# R7FA8D1BH register map
Vendor: Renesas; Series: RA8; File version: 1.2
CPU: CM85 r0p0, little endian, MPU, FPU, VTOR, 4 interrupt priority bits
Registers are 32-bit, read-write, reset 0x0 unless marked. A register's access mark holds for its fields unless they carry their own. Offsets are from the block's base; [hi:lo] are bit positions; lines under a group give offsets from that group; {n}, {i} and the like mark numbered series.

## WDT — Watchdog Timer
Base 0x40202600
Same registers: WDT_NS 0x50202600
0x00 WDTRR 8-bit reset 0xFF — WDT Refresh Register
  [7:0] WDTRR — WDTRR is an 8-bit register that refreshes the down-counter of the WDT.
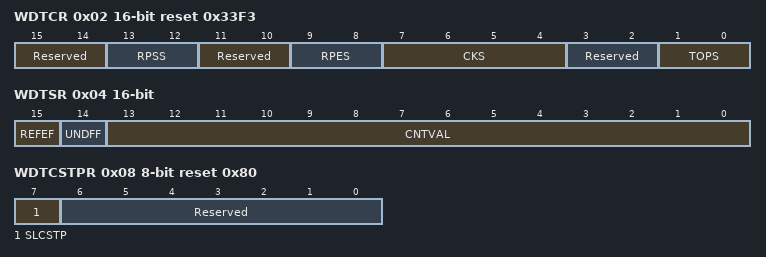
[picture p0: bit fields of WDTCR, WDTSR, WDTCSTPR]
0x02 WDTCR 16-bit reset 0x33F3 — WDT Control Register
  [15:14] Reserved — These bits are read as 00. The write value should be 00.
  [13:12] RPSS — Window Start Position Selection
    0=25 percent; 1=50 percent; 2=75 percent; 3=100 percent (window start position is not specified)
  [11:10] Reserved — These bits are read as 00. The write value should be 00.
  [9:8] RPES — Window End Position Selection
    0=75 percent; 1=50 percent; 2=25 percent; 3=0 percent (window end position is not specified)
  [7:4] CKS — Clock Division Ratio Selection
    1=PCLK/4; 4=PCLK/64; 15=PCLK/128; 6=PCLK/512; 7=PCLK/2048; 8=PCLK/8192; other=others (setting prohibited)
  [3:2] Reserved — These bits are read as 00. The write value should be 00.
  [1:0] TOPS — Timeout Period Selection
    0=1,024 cycles (03FFh); 1=4,096 cycles (0FFFh); 2=8,192 cycles (1FFFh); 3=16,384 cycles (3FFFh)
0x04 WDTSR 16-bit — WDT Status Register
  [15] REFEF write-0-clears read-modifies — Refresh Error Flag
    0=No refresh error occurred; 1=Refresh error occurred
  [14] UNDFF write-0-clears read-modifies — Underflow Flag
    0=No underflow occurred; 1=Underflow occurred
  [13:0] CNTVAL ro — Down-Counter ValueValue counted by the down-counter
0x06 WDTRCR 8-bit reset 0x80 — WDT Reset Control Register
  [7] RSTIRQS — Reset Interrupt Request Selection
    0=Non-maskable interrupt request or interrupt request output is enabled; 1=Reset output is enabled
0x08 WDTCSTPR 8-bit reset 0x80 — WDT Count Stop Control Register
  [7] SLCSTP — Sleep-Mode Count Stop Control
    0=Count stop is disabled; 1=Count is stopped at a transition to sleep mode
  [6:0] Reserved — These bits are read as 0000000. The write value should be 0000000.

## POEG — Port Output Enable Module for GPT
Base 0x40212000
Same registers: POEG_NS 0x50212000
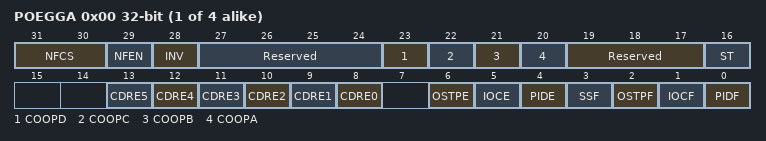
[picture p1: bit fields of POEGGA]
0x00 POEGG{x} (x=A,B,C,D; step 0x100) — POEG Group {x} Setting Register
  [31:30] NFCS — Noise Filter Clock Select
    0=Sampling GTETRG pin input level for three times in every PCLKB; 1=Sampling GTETRG pin input level for three times in every PCLKB /8; 2=Sampling GTETRG pin input level for three times in every PCLKB /32; 3=Sampling GTETRG pin input level for three times in every PCLKB /128
  [29] NFEN — Noise Filter Enable
    0=Filtering noise disabled; 1=Filtering noise enabled
  [28] INV — GTETRG Input Reverse
    0=GTETRG Input; 1=GTETRG Input Reversed
  [27:24] Reserved — These bits are read as 0000. The write value should be 0000.
  [23] COOPD — POEG group D Cooperation Enable
    0=Disable cooperation with POEG group D; 1=Enable cooperation with POEG group D
  [22] COOPC — POEG group C Cooperation Enable
    0=Disable cooperation with POEG group C; 1=Enable cooperation with POEG group C
  [21] COOPB — POEG group B Cooperation Enable
    0=Disable cooperation with POEG group B; 1=Enable cooperation with POEG group B
  [20] COOPA — POEG group A Cooperation Enable
    0=Disable cooperation with POEG group A; 1=Enable cooperation with POEG group A
  [19:17] Reserved — These bits are read as 000. The write value should be 000.
  [16] ST ro — GTETRG Input Status Flag
    0=GTETRG input after filtering is 0; 1=GTETRG input after filtering is 1
  [n+8] CDRE{n} (n=0..5) — Comparator Disable Request Enable {n}Note: Can be modified only once after a reset.
    0=A disable request of comparator {n} disabled; 1=A disable request of comparator {n} enabled
  [6] OSTPE — Oscillation Stop Detection EnableNote: Can be modified only once after a reset.
    0=A output-disable request from the oscillation stop detection disabled; 1=A output-disable request from the oscillation stop detection enabled
  [5] IOCE — Enable for GPT Output-Disable RequestNote: Can be modified only once after a reset.
    0=Disable output-disable requests from GPT disable request; 1=Enable output-disable requests from GPT disable request
  [4] PIDE — Port Input Detection EnableNote: Can be modified only once after a reset.
    0=A output-disable request from the GTETRG pins disabled; 1=A output-disable request from the GTETRG pins enabled
  [3] SSF — Software Stop Flag
    0=A output-disable request from software has not been generated; 1=A output-disable request from software has been generated
  [2] OSTPF write-0-clears read-modifies — Oscillation Stop Detection Flag
    0=A output-disable request from the oscillation stop detection has not been generated; 1=A output-disable request from the oscillation stop detection has been generated
  [1] IOCF write-0-clears read-modifies — Real Time Overcurrent Detection Flag
    0=A output-disable request from GPT disable request or comparator interrupt has not been generated; 1=A output-disable request from GPT disable request or comparator interrupt has been generated
  [0] PIDF write-0-clears read-modifies — Port Input Detection Flag
    0=A output-disable request from the GTETRG pin has not been generated; 1=A output-disable request from the GTETRG pin has been generated
